# SIMG301M113WIH register map
Vendor: Silicon Labs; Series: Si; File version: B
Registers are 32-bit, read-write, reset 0x0 unless marked. A register's access mark holds for its fields unless they carry their own. Offsets are from the block's base; [hi:lo] are bit positions; {n}, {i} and the like mark numbered series.

## SCRATCHPAD_NS — SCRATCHPAD_NS Registers
Base 0xA3004000
Same registers: SCRATCHPAD_S 0xB3004000
0x00 SREG0 — Used for SIMCTRL Pointer in Verification Environment
  [31:0] SCRATCH — Scratch Pad Register
0x04 SREG1 — Used for SIMCTRL Data Access in Verification Environment
  [31:0] SCRATCH

## SEMAILBOX_NS_HOST — SEMAILBOX_NS_HOST Registers
Base 0x42800000
Same registers: SEMAILBOX_S_HOST 0x52800000
0x00 FIFO — A write access to any address in this area will be mapped to the TX FIFO (only for the payload). A read access to any address in this area will be mapped to the RX FIFO (only for the payload). Using an address range (16 x 32-bit) rather than one single address mapped to the FIFO allows using incremental bursts.
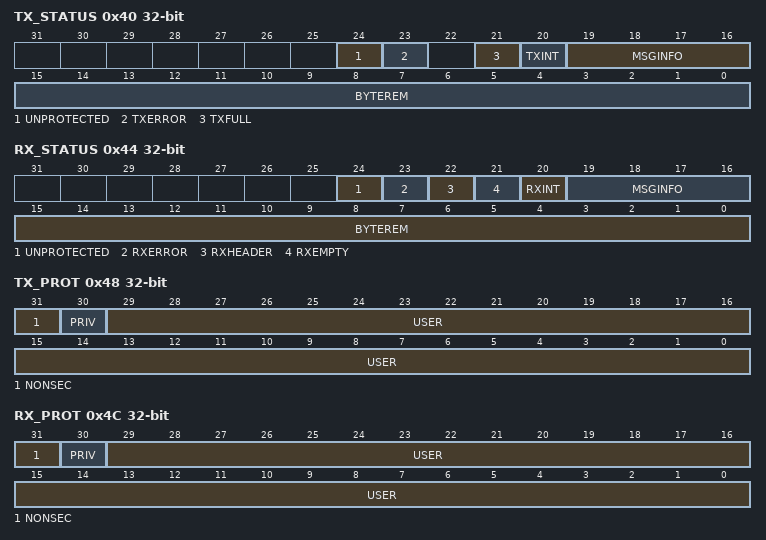
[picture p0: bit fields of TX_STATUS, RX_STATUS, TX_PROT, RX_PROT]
0x40 TX_STATUS ro
  [24] UNPROTECTED, [23] TXERROR, [21] TXFULL, [20] TXINT, [19:16] MSGINFO, [15:0] BYTEREM
0x44 RX_STATUS ro
  [24] UNPROTECTED, [23] RXERROR, [22] RXHEADER, [21] RXEMPTY, [20] RXINT, [19:16] MSGINFO, [15:0] BYTEREM
0x48 TX_PROT ro — TX Protection register.
  [31] NONSEC, [30] PRIV, [29:0] USER
0x4C RX_PROT ro — RX Protection register.
  [31] NONSEC, [30] PRIV, [29:0] USER
0x50 TX_HEADER wo — A write access to this register will be mapped to the TX FIFO (only for header).
  [31:0] TXHEADER
0x54 RX_HEADER ro — A read access to this register will be mapped to the RX FIFO (only for the header).
  [31:0] RXHEADER
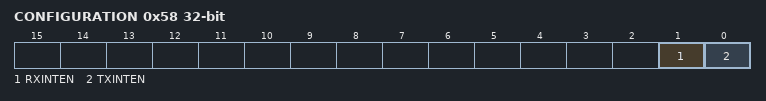
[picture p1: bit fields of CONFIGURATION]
0x58 CONFIGURATION
  [1] RXINTEN, [0] TXINTEN

## SEMAPHORE0_NS — SEMAPHORE0_NS Registers
Base 0x4082C000
Same registers: SEMAPHORE1_NS 0x40830000, SEMAPHORE0_S 0x5082C000, SEMAPHORE1_S 0x50830000
0x00 IPVERSION ro reset 0x1
  [31:0] IPVERSION — IP version ID
{0x4+4i} LOCK{i} (i=0..127)
  [0] LOCK{i} — SEMAPHORE LOCK {i} Bit Register

## SEPORTAL_NS — SEPORTAL_NS Registers
Base 0xA3010000
Same registers: SEPORTAL_S 0xB3010000
0x10 IPID ro reset 0x1
  [31:0] IPVERSION — IP version ID
0x14 CTRL
  [0] LPW0PWRUPREQ — LPW0 Power Up Request
0x18 STATUS
  [0] LPW0PWRUPACK — LPW0 Power up status

## SOCPLL0_NS — SOCPLL0_NS Registers
Base 0x40800000
Same registers: SOCPLL0_S 0x50800000
0x00 IPVERSION ro reset 0x2
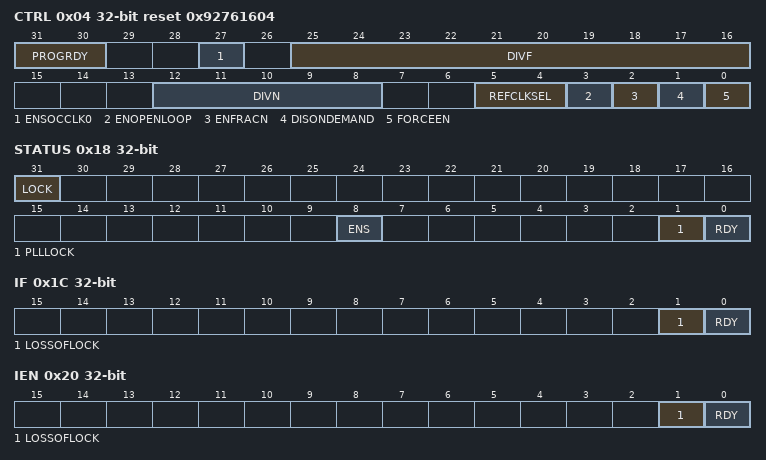
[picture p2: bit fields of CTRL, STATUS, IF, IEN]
0x04 CTRL reset 0x92761604
  [31:30] PROGRDY — Programmable RDY delay
    0=RDY_DELAY_0US (0us delay for rdy generation); 1=RDY_DELAY_4US (4us delay for rdy generation); 2=RDY_DELAY_8US (8us delay for rdy generation); 3=RDY_DELAY_16US (16us delay for rdy generation)
  [27] ENSOCCLK0 — Enable flash phy clock
  [25:16] DIVF — Fractional divider value
  [12:8] DIVN — Integer divider value
  [5:4] REFCLKSEL — Refrence clock source selection
    0=REF_HFXO (Select HFXO as reference clock); 1=REF_HFRCO (Select HFRCO as reference clock); 2=REF_EXTCLK (Select external clock as reference clock)
  [3] ENOPENLOOP — Open loop mode enable
  [2] ENFRACN — Frac-N Mode Enable
  [1] DISONDEMAND — Disable on Demand
  [0] FORCEEN — Force Enable
0x18 STATUS ro
  [31] LOCK — Lock Status
    0=UNLOCKED (SOCPLL is unlocked); 1=LOCKED (SOCPLL is locked)
  [8] ENS — SOCPLL Enable
  [1] PLLLOCK — Goes high within TDC range
  [0] RDY — SOCPLL Ready
0x1C IF
  [1] LOSSOFLOCK — Loss of PLL Lock Flag
  [0] RDY — Ready Interrupt Flag
0x20 IEN
  [1] LOSSOFLOCK — LOSSOFLOCK Interrupt Enable
  [0] RDY — RDY Interrupt Enable
0x24 LOCK wo reset 0x81A6
  [15:0] LOCKKEY — Configuration Lock Key
    0x81A6=UNLOCK (Write this value to unlock)

## SYSCFG_NS — SYSCFG_NS Registers
Base 0x40874000
Same registers: SYSCFG_S 0x50874000
0x04 IPVERSION ro reset 0xA
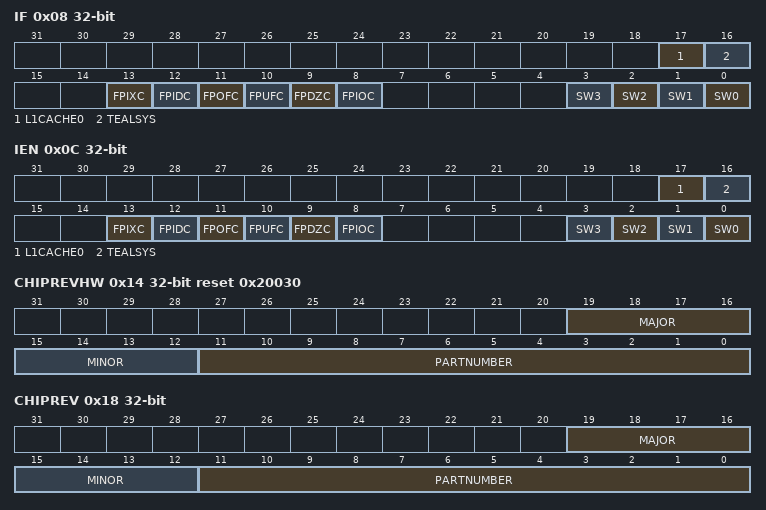
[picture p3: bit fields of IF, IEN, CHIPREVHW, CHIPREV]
0x08 IF — Read to get system status.
  [17] L1CACHE0 — L1CACHE bus error
  [16] TEALSYS — TEALSYS bus error
  [13] FPIXC — FPU Inexact interrupt flag
  [12] FPIDC — FPU Input denormal interrupt flag
  [11] FPOFC — FPU Overflow interrupt flag
  [10] FPUFC — FPU Underflow interrupt flag
  [9] FPDZC — FPU Divide by zero interrupt flag
  [8] FPIOC — FPU Invalid Operation interrupt flag
  [n] SW{n} (n=0..3) — Software Interrupt Flag
0x0C IEN — Write to enable interrupts.
  [17] L1CACHE0 — L1CACHE bus error enable
  [16] TEALSYS — TEALSYS bus error enable
  [13] FPIXC — FPU Inexact Interrupt Enable
  [12] FPIDC — FPU Input denormal Interrupt Enable
  [11] FPOFC — FPU Overflow Interrupt Enable
  [10] FPUFC — FPU Underflow Interrupt Enable
  [9] FPDZC — FPU Divide by zero Interrupt Enable
  [8] FPIOC — FPU Invalid Operation Interrupt Enable
  [n] SW{n} (n=0..3) — Software Interrupt Enable
0x14 CHIPREVHW reset 0x20030 — Read to get the hard-wired chip revision.
  [19:16] MAJOR ro — Hardwired Chip Major value
  [15:12] MINOR ro — Hardwired Chip Minor value
  [11:0] PARTNUMBER — Chip Part Number value
0x18 CHIPREV — Read to get the chip revision programmed by feature configuration.
  [19:16] MAJOR — Chip Revision Major value
  [15:12] MINOR — Chip Revision Minor value
  [11:0] PARTNUMBER — Chip Part Number value
0x24 CFGSYSTIC — Configure the source of the system tick for the M33.
  [0] SYSTICEXTCLKEN — SysTick External Clock Enable
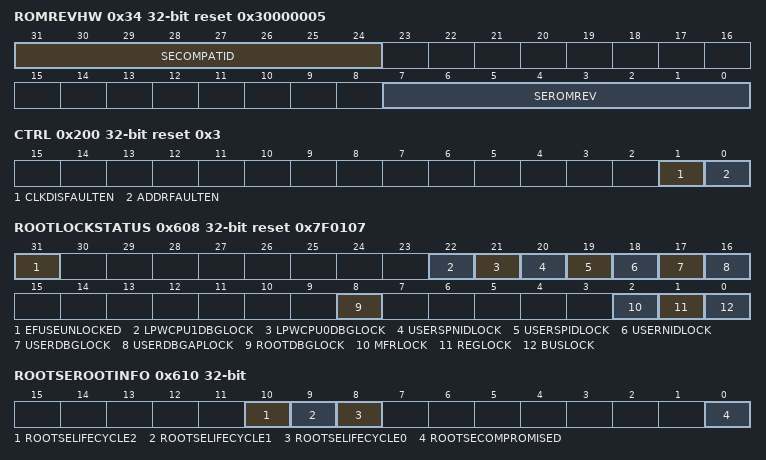
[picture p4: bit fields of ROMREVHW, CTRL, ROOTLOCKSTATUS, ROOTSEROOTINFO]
0x34 ROMREVHW ro reset 0x30000005 — Read to get the hard-wired ROM revision.
  [31:24] SECOMPATID, [7:0] SEROMREV
0x200 CTRL reset 0x3 — Configure to provide general RAM configuration.
  [1] CLKDISFAULTEN — Disabled Clkbus Bus Fault Enable
  [0] ADDRFAULTEN — Invalid Address Bus Fault Response Enabl
0x600 ROOTDATA0 — Generic data space for user to pass to root, e.g., address of struct in mem
  [31:0] DATA
0x604 ROOTDATA1 — Generic data space for user to pass to root, e.g., address of struct in mem
  [31:0] DATA
0x608 ROOTLOCKSTATUS ro reset 0x7F0107 — This register returns the status of the SE managed locks.
  [31] EFUSEUNLOCKED
  [22] LPWCPU1DBGLOCK — LPW CPU1 Debug Lock
  [21] LPWCPU0DBGLOCK — LPW CPU0 Debug Lock
  [20] USERSPNIDLOCK — User Secure Non-invasive Debug Lock
  [19] USERSPIDLOCK — User Secure Invasive Debug Lock
  [18] USERNIDLOCK — User Non-invasive Debug Lock
  [17] USERDBGLOCK — User Invasive Debug Lock
  [16] USERDBGAPLOCK — User Debug Access Port Lock
  [8] ROOTDBGLOCK — Root Debug Lock
  [2] MFRLOCK — Manufacture Lock
  [1] REGLOCK — Register Lock
  [0] BUSLOCK
0x60C ROOTSESWVERSION — SE Software version
  [31:0] SWVERSION
0x610 ROOTSEROOTINFO — SE Root Information
  [10] ROOTSELIFECYCLE2, [9] ROOTSELIFECYCLE1, [8] ROOTSELIFECYCLE0, [0] ROOTSECOMPROMISED
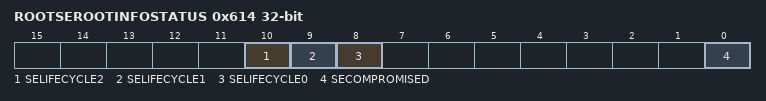
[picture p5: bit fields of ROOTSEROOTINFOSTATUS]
0x614 ROOTSEROOTINFOSTATUS ro — SE Root Information Status
  [10] SELIFECYCLE2, [9] SELIFECYCLE1, [8] SELIFECYCLE0, [0] SECOMPROMISED
